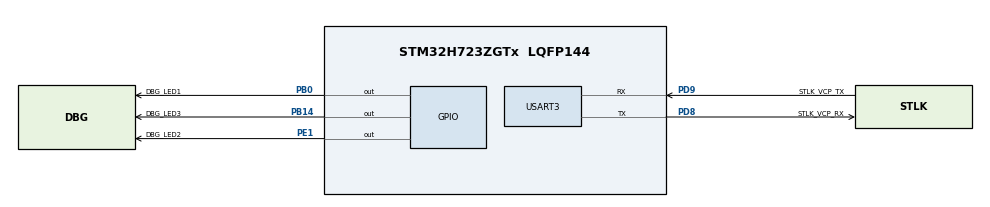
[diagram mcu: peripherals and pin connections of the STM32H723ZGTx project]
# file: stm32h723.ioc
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CORTEX_M7.CPU_ICache=Enabled
CORTEX_M7.default_mode_Activation=1
FREERTOS.Tasks01=defaultTask,24,128,StartDefaultTask,Default,NULL,Dynamic,NULL,NULL
FREERTOS.configTOTAL_HEAP_SIZE=32768
Mcu.Family=STM32H7
Mcu.Name=STM32H723ZGTx
Mcu.Package=LQFP144
NVIC.PriorityGroup=NVIC_PRIORITYGROUP_4
NVIC.TIM6_DAC_IRQn=true\:15\:0\:false\:false\:true\:false\:false\:true\:true
NVIC.TimeBase=TIM6_DAC_IRQn
NVIC.TimeBaseIP=TIM6
PA13(JTMS/SWDIO).GPIO_Label=SWDIO
PA13(JTMS/SWDIO).Mode=Serial_Wire
PA13(JTMS/SWDIO).Signal=DEBUG_JTMS-SWDIO
PA14(JTCK/SWCLK).GPIO_Label=SWCLK
PA14(JTCK/SWCLK).Mode=Serial_Wire
PA14(JTCK/SWCLK).Signal=DEBUG_JTCK-SWCLK
PB0.GPIO_Label=DBG_LED1
PB0.Signal=GPIO_Output
PB14.GPIO_Label=DBG_LED3
PB14.Signal=GPIO_Output
PC14-OSC32_IN.Signal=RCC_OSC32_IN
PC15-OSC32_OUT.Signal=RCC_OSC32_OUT
PD8.GPIO_Label=STLK_VCP_RX
PD8.Mode=Asynchronous
PD8.Signal=USART3_TX
PD9.GPIO_Label=STLK_VCP_TX
PD9.Mode=Asynchronous
PD9.Signal=USART3_RX
PE1.GPIO_Label=DBG_LED2
PE1.Signal=GPIO_Output
PH0-OSC_IN.Mode=HSE-External-Clock-Source
PH0-OSC_IN.Signal=RCC_OSC_IN
ProjectManager.HeapSize=0x200
ProjectManager.StackSize=0x400
ProjectManager.TargetToolchain=CMake
RCC.ADCFreq_Value=608000000
RCC.APB1Freq_Value=100000000
RCC.APB2Freq_Value=100000000
RCC.APB3Freq_Value=100000000
RCC.APB4Freq_Value=100000000
RCC.CortexFreq_Value=400000000
RCC.D1PPRE=RCC_APB3_DIV2
RCC.D2PPRE1=RCC_APB1_DIV2
RCC.D2PPRE2=RCC_APB2_DIV2
RCC.D3PPRE=RCC_APB4_DIV2
RCC.DIVM1=4
RCC.DIVM2=1
RCC.DIVN1=25
RCC.DIVN2=19
RCC.DIVP1=1
RCC.DIVQ1=4
RCC.HCLKFreq_Value=200000000
RCC.HPRE=RCC_HCLK_DIV2
RCC.HSE_VALUE=8000000
RCC.PLLFRACN=0
RCC.SYSCLKFreq_VALUE=400000000
RCC.SYSCLKSource=RCC_SYSCLKSOURCE_PLLCLK
RCC.USBCLockSelection=RCC_USBCLKSOURCE_HSI48
RCC.USBFreq_Value=48000000
USART3.VirtualMode-Asynchronous=VM_ASYNC
VP_FREERTOS_VS_CMSIS_V2.Mode=CMSIS_V2
VP_MEMORYMAP_VS_MEMORYMAP.Mode=CurAppReg
VP_SYS_VS_tim6.Mode=TIM6
board=NUCLEO-H723ZG

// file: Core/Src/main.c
/* USER CODE BEGIN Header */
/**
  ******************************************************************************
  * @file           : main.c
  * @brief          : Main program body
  ******************************************************************************
  * @attention
  *
  * Copyright (c) 2026 STMicroelectronics.
  * All rights reserved.
  *
  * This software is licensed under terms that can be found in the LICENSE file
  * in the root directory of this software component.
  * If no LICENSE file comes with this software, it is provided AS-IS.
  *
  ******************************************************************************
  */
/* USER CODE END Header */
#include "main.h"
#include "FreeRTOS.h"
#include "cmsis_os2.h"
#include "usart.h"
#include "gpio.h"

void SystemClock_Config(void);
static void MPU_Config(void);
void MX_FREERTOS_Init(void);

int main(void)
{

  /* MPU Configuration--------------------------------------------------------*/
  MPU_Config();

  /* Enable the CPU Cache */

  /* Enable I-Cache---------------------------------------------------------*/
  SCB_EnableICache();

  /* MCU Configuration--------------------------------------------------------*/

  /* Reset of all peripherals, Initializes the Flash interface and the Systick. */
  HAL_Init();

  /* Configure the system clock */
  SystemClock_Config();

  /* Initialize all configured peripherals */
  MX_GPIO_Init();
  MX_USART3_UART_Init();

  /* Init scheduler */
  osKernelInitialize();  /* Call init function for freertos objects (in cmsis_os2.c) */
  MX_FREERTOS_Init();

  /* Start scheduler */
  osKernelStart();

  /* We should never get here as control is now taken by the scheduler */

  /* Infinite loop */
  while (1)
  {

  }
}

void SystemClock_Config(void)
{
  RCC_OscInitTypeDef RCC_OscInitStruct = {0};
  RCC_ClkInitTypeDef RCC_ClkInitStruct = {0};

  /** Supply configuration update enable
  */
  HAL_PWREx_ConfigSupply(PWR_LDO_SUPPLY);

  /** Configure the main internal regulator output voltage
  */
  __HAL_PWR_VOLTAGESCALING_CONFIG(PWR_REGULATOR_VOLTAGE_SCALE1);

  while(!__HAL_PWR_GET_FLAG(PWR_FLAG_VOSRDY)) {}

  /** Initializes the RCC Oscillators according to the specified parameters
  * in the RCC_OscInitTypeDef structure.
  */
  RCC_OscInitStruct.OscillatorType = RCC_OSCILLATORTYPE_HSI;
  RCC_OscInitStruct.HSIState = RCC_HSI_DIV1;
  RCC_OscInitStruct.HSICalibrationValue = 64;
  RCC_OscInitStruct.PLL.PLLState = RCC_PLL_ON;
  RCC_OscInitStruct.PLL.PLLSource = RCC_PLLSOURCE_HSI;
  RCC_OscInitStruct.PLL.PLLM = 4;
  RCC_OscInitStruct.PLL.PLLN = 25;
  RCC_OscInitStruct.PLL.PLLP = 1;
  RCC_OscInitStruct.PLL.PLLQ = 4;
  RCC_OscInitStruct.PLL.PLLR = 2;
  RCC_OscInitStruct.PLL.PLLRGE = RCC_PLL1VCIRANGE_3;
  RCC_OscInitStruct.PLL.PLLVCOSEL = RCC_PLL1VCOWIDE;
  RCC_OscInitStruct.PLL.PLLFRACN = 0;
  if (HAL_RCC_OscConfig(&RCC_OscInitStruct) != HAL_OK)
  {
    Error_Handler();
  }

  /** Initializes the CPU, AHB and APB buses clocks
  */
  RCC_ClkInitStruct.ClockType = RCC_CLOCKTYPE_HCLK|RCC_CLOCKTYPE_SYSCLK
                              |RCC_CLOCKTYPE_PCLK1|RCC_CLOCKTYPE_PCLK2
                              |RCC_CLOCKTYPE_D3PCLK1|RCC_CLOCKTYPE_D1PCLK1;
  RCC_ClkInitStruct.SYSCLKSource = RCC_SYSCLKSOURCE_PLLCLK;
  RCC_ClkInitStruct.SYSCLKDivider = RCC_SYSCLK_DIV1;
  RCC_ClkInitStruct.AHBCLKDivider = RCC_HCLK_DIV2;
  RCC_ClkInitStruct.APB3CLKDivider = RCC_APB3_DIV2;
  RCC_ClkInitStruct.APB1CLKDivider = RCC_APB1_DIV2;
  RCC_ClkInitStruct.APB2CLKDivider = RCC_APB2_DIV2;
  RCC_ClkInitStruct.APB4CLKDivider = RCC_APB4_DIV2;

  if (HAL_RCC_ClockConfig(&RCC_ClkInitStruct, FLASH_LATENCY_2) != HAL_OK)
  {
    Error_Handler();
  }
}

 /* MPU Configuration */

void MPU_Config(void)
{
  MPU_Region_InitTypeDef MPU_InitStruct = {0};

  /* Disables the MPU */
  HAL_MPU_Disable();

  /** Initializes and configures the Region and the memory to be protected
  */
  MPU_InitStruct.Enable = MPU_REGION_ENABLE;
  MPU_InitStruct.Number = MPU_REGION_NUMBER0;
  MPU_InitStruct.BaseAddress = 0x0;
  MPU_InitStruct.Size = MPU_REGION_SIZE_4GB;
  MPU_InitStruct.SubRegionDisable = 0x87;
  MPU_InitStruct.TypeExtField = MPU_TEX_LEVEL0;
  MPU_InitStruct.AccessPermission = MPU_REGION_NO_ACCESS;
  MPU_InitStruct.DisableExec = MPU_INSTRUCTION_ACCESS_DISABLE;
  MPU_InitStruct.IsShareable = MPU_ACCESS_SHAREABLE;
  MPU_InitStruct.IsCacheable = MPU_ACCESS_NOT_CACHEABLE;
  MPU_InitStruct.IsBufferable = MPU_ACCESS_NOT_BUFFERABLE;

  HAL_MPU_ConfigRegion(&MPU_InitStruct);
  /* Enables the MPU */
  HAL_MPU_Enable(MPU_PRIVILEGED_DEFAULT);

}

void HAL_TIM_PeriodElapsedCallback(TIM_HandleTypeDef *htim)
{
  if (htim->Instance == TIM6)
  {
    HAL_IncTick();
  }
}

void Error_Handler(void)
{
  __disable_irq();
  while (1)
  {
  }
}

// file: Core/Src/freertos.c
/* USER CODE BEGIN Header */
/**
  ******************************************************************************
  * File Name          : freertos.c
  * Description        : Code for freertos applications
  ******************************************************************************
  * @attention
  *
  * Copyright (c) 2026 STMicroelectronics.
  * All rights reserved.
  *
  * This software is licensed under terms that can be found in the LICENSE file
  * in the root directory of this software component.
  * If no LICENSE file comes with this software, it is provided AS-IS.
  *
  ******************************************************************************
  */
/* USER CODE END Header */

#include "FreeRTOS.h"
#include "task.h"
#include "main.h"
#include "FreeRTOS.h"
#include "cmsis_os2.h"

/* USER CODE BEGIN Includes */
#include "app_main.h"
/* USER CODE END Includes */

/* Definitions for defaultTask */
osThreadId_t defaultTaskHandle;
const osThreadAttr_t defaultTask_attributes = {
  .name = "defaultTask",
  .stack_size = 128 * 4,
  .priority = (osPriority_t) osPriorityNormal,
};

void StartDefaultTask(void *argument);

void MX_FREERTOS_Init(void); /* (MISRA C 2004 rule 8.1) */

void MX_FREERTOS_Init(void) {

  /* Create the thread(s) */
  /* creation of defaultTask */
  defaultTaskHandle = osThreadNew(StartDefaultTask, NULL, &defaultTask_attributes);

  /* USER CODE BEGIN RTOS_THREADS */
  /* add threads, ... */
  app_main_create_tasks();
  /* USER CODE END RTOS_THREADS */

}

void StartDefaultTask(void *argument)
{
  /* USER CODE BEGIN StartDefaultTask */
  /* Infinite loop */
  for(;;)
  {
    osDelay(1000);
  }
  /* USER CODE END StartDefaultTask */
}
